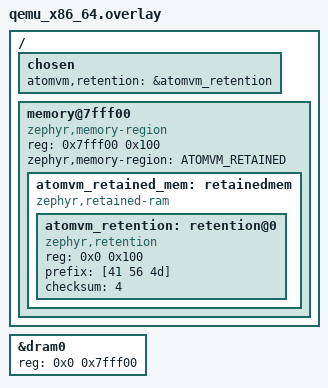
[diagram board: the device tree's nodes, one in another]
/*
 * This file is part of AtomVM.
 *
 * Copyright 2026 Peter M <petermm@gmail.com>
 *
 * SPDX-License-Identifier: Apache-2.0 OR LGPL-2.1-or-later
 */

/ {
	chosen {
		atomvm,retention = &atomvm_retention;
	};

	memory@7fff00 {
		compatible = "zephyr,memory-region", "mmio-sram";
		reg = <0x7fff00 0x100>;
		ranges = <0x0 0x7fff00 0x100>;
		zephyr,memory-region = "ATOMVM_RETAINED";
		status = "okay";
		#address-cells = <1>;
		#size-cells = <1>;

		atomvm_retained_mem: retainedmem {
			compatible = "zephyr,retained-ram";
			status = "okay";
			ranges;
			#address-cells = <1>;
			#size-cells = <1>;

			atomvm_retention: retention@0 {
				compatible = "zephyr,retention";
				status = "okay";
				reg = <0x0 0x100>;
				prefix = [41 56 4d];
				checksum = <4>;
			};
		};
	};
};

&dram0 {
	reg = <0x0 0x7fff00>;
};
